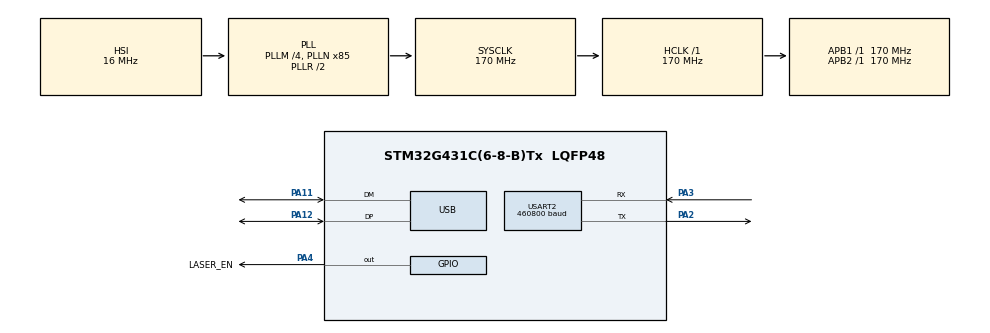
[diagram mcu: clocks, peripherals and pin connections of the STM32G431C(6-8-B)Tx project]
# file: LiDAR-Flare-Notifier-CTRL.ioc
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Dma.Request0=USART2_RX
Dma.USART2_RX.0.Direction=DMA_PERIPH_TO_MEMORY
Dma.USART2_RX.0.EventEnable=DISABLE
Dma.USART2_RX.0.Instance=DMA1_Channel1
Dma.USART2_RX.0.MemDataAlignment=DMA_MDATAALIGN_BYTE
Dma.USART2_RX.0.MemInc=DMA_MINC_ENABLE
Dma.USART2_RX.0.Mode=DMA_CIRCULAR
Dma.USART2_RX.0.PeriphDataAlignment=DMA_PDATAALIGN_BYTE
Dma.USART2_RX.0.PeriphInc=DMA_PINC_DISABLE
Dma.USART2_RX.0.Polarity=HAL_DMAMUX_REQ_GEN_RISING
Dma.USART2_RX.0.Priority=DMA_PRIORITY_LOW
Dma.USART2_RX.0.RequestNumber=1
Dma.USART2_RX.0.SignalID=NONE
Dma.USART2_RX.0.SyncEnable=DISABLE
Dma.USART2_RX.0.SyncPolarity=HAL_DMAMUX_SYNC_NO_EVENT
Dma.USART2_RX.0.SyncRequestNumber=1
Dma.USART2_RX.0.SyncSignalID=NONE
IWDG.Prescaler=IWDG_PRESCALER_32
IWDG.Reload=1000
Mcu.Family=STM32G4
Mcu.Name=STM32G431C(6-8-B)Tx
Mcu.Package=LQFP48
NVIC.DMA1_Channel1_IRQn=true\:0\:0\:false\:false\:true\:false\:true\:true
NVIC.PriorityGroup=NVIC_PRIORITYGROUP_4
NVIC.USART2_IRQn=true\:0\:0\:false\:false\:true\:true\:true\:true
NVIC.USB_LP_IRQn=true\:0\:0\:false\:false\:true\:false\:true\:true
PA11.Mode=Device
PA11.Signal=USB_DM
PA12.Mode=Device
PA12.Signal=USB_DP
PA13.Mode=Serial_Wire
PA13.Signal=SYS_JTMS-SWDIO
PA14.Mode=Serial_Wire
PA14.Signal=SYS_JTCK-SWCLK
PA2.Mode=Asynchronous
PA2.Signal=USART2_TX
PA3.Mode=Asynchronous
PA3.Signal=USART2_RX
PA4.GPIO_Label=LASER_EN
PA4.PinState=GPIO_PIN_SET
PA4.Signal=GPIO_Output
ProjectManager.HeapSize=0x600
ProjectManager.StackSize=0x800
ProjectManager.TargetToolchain=CMake
RCC.ADC12Freq_Value=170000000
RCC.AHBFreq_Value=170000000
RCC.APB1Freq_Value=170000000
RCC.APB1TimFreq_Value=170000000
RCC.APB2Freq_Value=170000000
RCC.APB2TimFreq_Value=170000000
RCC.CK48CLockSelection=RCC_USBCLKSOURCE_HSI48
RCC.CortexFreq_Value=170000000
RCC.EXTERNAL_CLOCK_VALUE=12288000
RCC.HCLKFreq_Value=170000000
RCC.HSE_VALUE=8000000
RCC.HSI48_VALUE=48000000
RCC.HSI_VALUE=16000000
RCC.LSE_VALUE=32768
RCC.PLLM=RCC_PLLM_DIV4
RCC.PLLN=85
RCC.SYSCLKFreq_VALUE=170000000
RCC.SYSCLKSource=RCC_SYSCLKSOURCE_PLLCLK
RCC.USBFreq_Value=48000000
RCC.VCOOutputFreq_Value=340000000
USART2.BaudRate=460800
USART2.VirtualMode-Asynchronous=VM_ASYNC
USB_DEVICE.CLASS_NAME_FS=CDC
USB_DEVICE.VirtualMode=Cdc
USB_DEVICE.VirtualModeFS=Cdc_FS
VP_IWDG_VS_IWDG.Mode=IWDG_Activate
VP_RCC_VS_USB.Mode=USB_FS
VP_SYS_VS_DBSignals.Mode=DisableDeadBatterySignals
VP_USB_DEVICE_VS_USB_DEVICE_CDC_FS.Mode=CDC_FS
board=custom

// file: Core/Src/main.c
/* USER CODE BEGIN Header */
/**
  ******************************************************************************
  * @file           : main.c
  * @brief          : Main program body
  ******************************************************************************
  * @attention
  *
  * Copyright (c) 2026 STMicroelectronics.
  * All rights reserved.
  *
  * This software is licensed under terms that can be found in the LICENSE file
  * in the root directory of this software component.
  * If no LICENSE file comes with this software, it is provided AS-IS.
  *
  ******************************************************************************
  */
/* USER CODE END Header */
#include "main.h"
#include "dma.h"
#include "iwdg.h"
#include "usart.h"
#include "usb_device.h"
#include "gpio.h"

/* USER CODE BEGIN Includes */
#include "app.h"
/* USER CODE END Includes */

void SystemClock_Config(void);

int main(void)
{

  /* MCU Configuration--------------------------------------------------------*/

  /* Reset of all peripherals, Initializes the Flash interface and the Systick. */
  HAL_Init();

  /* Configure the system clock */
  SystemClock_Config();

  /* Initialize all configured peripherals */
  MX_GPIO_Init();
  MX_DMA_Init();
  MX_IWDG_Init();
  MX_USART2_UART_Init();
  MX_USB_Device_Init();
  /* USER CODE BEGIN 2 */
  app_init();
  /* USER CODE END 2 */

  /* Infinite loop */
  while (1)
  {

    /* USER CODE BEGIN 3 */
    app_poll();
    HAL_IWDG_Refresh(&hiwdg);
  }
  /* USER CODE END 3 */
}

void SystemClock_Config(void)
{
  RCC_OscInitTypeDef RCC_OscInitStruct = {0};
  RCC_ClkInitTypeDef RCC_ClkInitStruct = {0};
  RCC_CRSInitTypeDef pInit = {0};

  /** Configure the main internal regulator output voltage
  */
  HAL_PWREx_ControlVoltageScaling(PWR_REGULATOR_VOLTAGE_SCALE1_BOOST);

  /** Initializes the RCC Oscillators according to the specified parameters
  * in the RCC_OscInitTypeDef structure.
  */
  RCC_OscInitStruct.OscillatorType = RCC_OSCILLATORTYPE_HSI|RCC_OSCILLATORTYPE_HSI48
                              |RCC_OSCILLATORTYPE_LSI;
  RCC_OscInitStruct.HSIState = RCC_HSI_ON;
  RCC_OscInitStruct.HSICalibrationValue = RCC_HSICALIBRATION_DEFAULT;
  RCC_OscInitStruct.LSIState = RCC_LSI_ON;
  RCC_OscInitStruct.HSI48State = RCC_HSI48_ON;
  RCC_OscInitStruct.PLL.PLLState = RCC_PLL_ON;
  RCC_OscInitStruct.PLL.PLLSource = RCC_PLLSOURCE_HSI;
  RCC_OscInitStruct.PLL.PLLM = RCC_PLLM_DIV4;
  RCC_OscInitStruct.PLL.PLLN = 85;
  RCC_OscInitStruct.PLL.PLLP = RCC_PLLP_DIV2;
  RCC_OscInitStruct.PLL.PLLQ = RCC_PLLQ_DIV2;
  RCC_OscInitStruct.PLL.PLLR = RCC_PLLR_DIV2;
  if (HAL_RCC_OscConfig(&RCC_OscInitStruct) != HAL_OK)
  {
    Error_Handler();
  }

  /** Initializes the CPU, AHB and APB buses clocks
  */
  RCC_ClkInitStruct.ClockType = RCC_CLOCKTYPE_HCLK|RCC_CLOCKTYPE_SYSCLK
                              |RCC_CLOCKTYPE_PCLK1|RCC_CLOCKTYPE_PCLK2;
  RCC_ClkInitStruct.SYSCLKSource = RCC_SYSCLKSOURCE_PLLCLK;
  RCC_ClkInitStruct.AHBCLKDivider = RCC_SYSCLK_DIV1;
  RCC_ClkInitStruct.APB1CLKDivider = RCC_HCLK_DIV1;
  RCC_ClkInitStruct.APB2CLKDivider = RCC_HCLK_DIV1;

  if (HAL_RCC_ClockConfig(&RCC_ClkInitStruct, FLASH_LATENCY_4) != HAL_OK)
  {
    Error_Handler();
  }

  /** Enable the SYSCFG APB clock
  */
  __HAL_RCC_CRS_CLK_ENABLE();

  /** Configures CRS
  */
  pInit.Prescaler = RCC_CRS_SYNC_DIV1;
  pInit.Source = RCC_CRS_SYNC_SOURCE_USB;
  pInit.Polarity = RCC_CRS_SYNC_POLARITY_RISING;
  pInit.ReloadValue = __HAL_RCC_CRS_RELOADVALUE_CALCULATE(48000000,1000);
  pInit.ErrorLimitValue = 34;
  pInit.HSI48CalibrationValue = 32;

  HAL_RCCEx_CRSConfig(&pInit);
}

void Error_Handler(void)
{
  __disable_irq();
  while (1)
  {
  }
}
